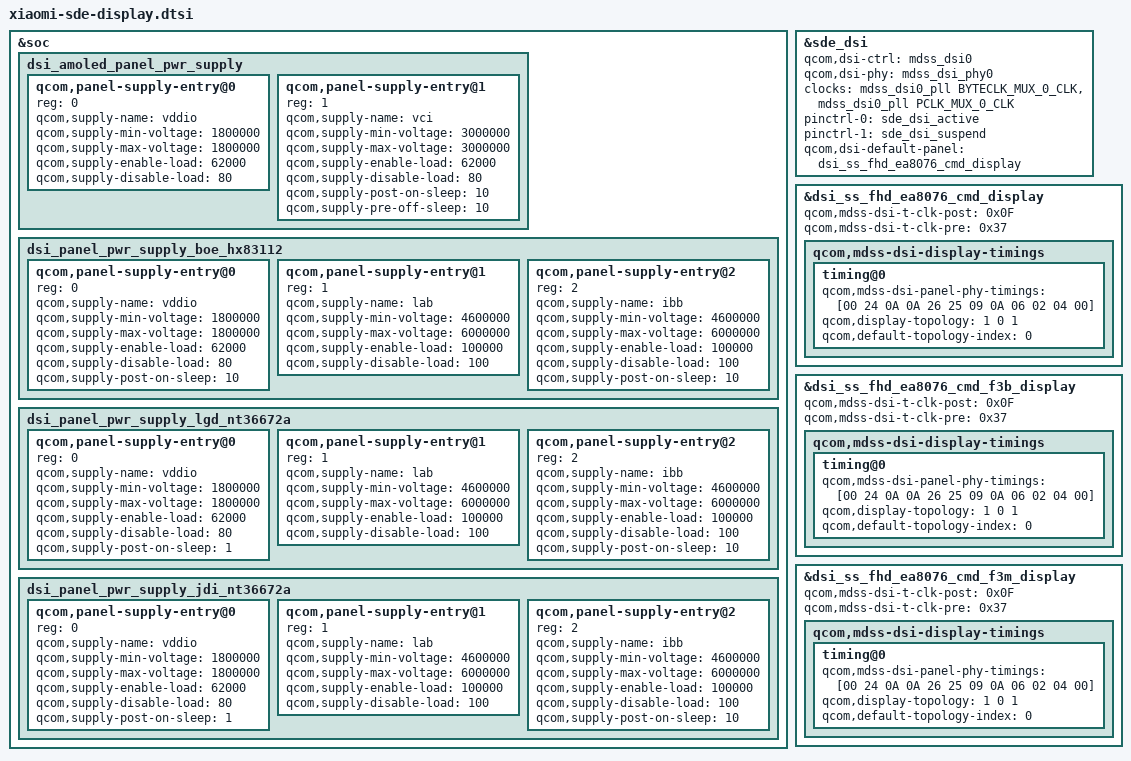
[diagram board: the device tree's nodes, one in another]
/* Copyright (c) 2017, The Linux Foundation. All rights reserved.
 * Copyright (C) 2020 XiaoMi, Inc.
 *
 * This program is free software; you can redistribute it and/or modify
 * it under the terms of the GNU General Public License version 2 and
 * only version 2 as published by the Free Software Foundation.
 *
 * This program is distributed in the hope that it will be useful,
 * but WITHOUT ANY WARRANTY; without even the implied warranty of
 * MERCHANTABILITY or FITNESS FOR A PARTICULAR PURPOSE.  See the
 * GNU General Public License for more details.
 */

#include "dsi-panel-samsung-fhd-ea8076-cmd.dtsi"
#include "dsi-panel-samsung-fhd-ea8076-cmd-f3b.dtsi"
#include "dsi-panel-samsung-fhd-ea8076-cmd-f3m.dtsi"

&soc {
	dsi_amoled_panel_pwr_supply: dsi_amoled_panel_pwr_supply {
		#address-cells = <1>;
		#size-cells = <0>;

		qcom,panel-supply-entry@0 {
			reg = <0>;
			qcom,supply-name = "vddio";
			qcom,supply-min-voltage = <1800000>;
			qcom,supply-max-voltage = <1800000>;
			qcom,supply-enable-load = <62000>;
			qcom,supply-disable-load = <80>;
		};

		qcom,panel-supply-entry@1 {
			reg = <1>;
			qcom,supply-name = "vci";
			qcom,supply-min-voltage = <3000000>;
			qcom,supply-max-voltage = <3000000>;
			qcom,supply-enable-load = <62000>;
			qcom,supply-disable-load = <80>;
			qcom,supply-post-on-sleep = <10>;
			qcom,supply-pre-off-sleep = <10>;
		};
	};

	dsi_panel_pwr_supply_boe_hx83112: dsi_panel_pwr_supply_boe_hx83112 {
		#address-cells = <1>;
		#size-cells = <0>;

		qcom,panel-supply-entry@0 {
			reg = <0>;
			qcom,supply-name = "vddio";
			qcom,supply-min-voltage = <1800000>;
			qcom,supply-max-voltage = <1800000>;
			qcom,supply-enable-load = <62000>;
			qcom,supply-disable-load = <80>;
			qcom,supply-post-on-sleep = <10>;
		};

		qcom,panel-supply-entry@1 {
			reg = <1>;
			qcom,supply-name = "lab";
			qcom,supply-min-voltage = <4600000>;
			qcom,supply-max-voltage = <6000000>;
			qcom,supply-enable-load = <100000>;
			qcom,supply-disable-load = <100>;
		};

		qcom,panel-supply-entry@2 {
			reg = <2>;
			qcom,supply-name = "ibb";
			qcom,supply-min-voltage = <4600000>;
			qcom,supply-max-voltage = <6000000>;
			qcom,supply-enable-load = <100000>;
			qcom,supply-disable-load = <100>;
			qcom,supply-post-on-sleep = <10>;
		};
	};

	dsi_panel_pwr_supply_lgd_nt36672a: dsi_panel_pwr_supply_lgd_nt36672a {
		#address-cells = <1>;
		#size-cells = <0>;

		qcom,panel-supply-entry@0 {
			reg = <0>;
			qcom,supply-name = "vddio";
			qcom,supply-min-voltage = <1800000>;
			qcom,supply-max-voltage = <1800000>;
			qcom,supply-enable-load = <62000>;
			qcom,supply-disable-load = <80>;
			qcom,supply-post-on-sleep = <1>;
		};

		qcom,panel-supply-entry@1 {
			reg = <1>;
			qcom,supply-name = "lab";
			qcom,supply-min-voltage = <4600000>;
			qcom,supply-max-voltage = <6000000>;
			qcom,supply-enable-load = <100000>;
			qcom,supply-disable-load = <100>;
		};

		qcom,panel-supply-entry@2 {
			reg = <2>;
			qcom,supply-name = "ibb";
			qcom,supply-min-voltage = <4600000>;
			qcom,supply-max-voltage = <6000000>;
			qcom,supply-enable-load = <100000>;
			qcom,supply-disable-load = <100>;
			qcom,supply-post-on-sleep = <10>;
		};
	};

	dsi_panel_pwr_supply_jdi_nt36672a: dsi_panel_pwr_supply_jdi_nt36672a {
	#address-cells = <1>;
	#size-cells = <0>;

		qcom,panel-supply-entry@0 {
			reg = <0>;
			qcom,supply-name = "vddio";
			qcom,supply-min-voltage = <1800000>;
			qcom,supply-max-voltage = <1800000>;
			qcom,supply-enable-load = <62000>;
			qcom,supply-disable-load = <80>;
			qcom,supply-post-on-sleep = <1>;
		};

		qcom,panel-supply-entry@1 {
			reg = <1>;
			qcom,supply-name = "lab";
			qcom,supply-min-voltage = <4600000>;
			qcom,supply-max-voltage = <6000000>;
			qcom,supply-enable-load = <100000>;
			qcom,supply-disable-load = <100>;
		};

		qcom,panel-supply-entry@2 {
			reg = <2>;
			qcom,supply-name = "ibb";
			qcom,supply-min-voltage = <4600000>;
			qcom,supply-max-voltage = <6000000>;
			qcom,supply-enable-load = <100000>;
			qcom,supply-disable-load = <100>;
			qcom,supply-post-on-sleep = <10>;
		};
	};
};

&sde_dsi {
	qcom,dsi-ctrl = <&mdss_dsi0>;
	qcom,dsi-phy = <&mdss_dsi_phy0>;


	clocks = <&mdss_dsi0_pll BYTECLK_MUX_0_CLK>,
			<&mdss_dsi0_pll PCLK_MUX_0_CLK>;
	clock-names = "mux_byte_clk0", "mux_pixel_clk0";
	pinctrl-names = "panel_active", "panel_suspend";
	pinctrl-0 = <&sde_dsi_active>;
	pinctrl-1 = <&sde_dsi_suspend>;
	/delete-property/ oled-vdda-supply;
	/delete-property/ qcom,platform-te-gpio;
	qcom,dsi-default-panel = <&dsi_ss_fhd_ea8076_cmd_display>;
};

&dsi_ss_fhd_ea8076_cmd_display  {
	qcom,mdss-dsi-t-clk-post = <0x0F>;
	qcom,mdss-dsi-t-clk-pre = <0x37>;
	qcom,mdss-dsi-display-timings {
		timing@0{
			qcom,mdss-dsi-panel-phy-timings = [00 24 0A 0A 26 25 09
				0A 06 02 04 00];
			qcom,display-topology = <1 0 1>;
			qcom,default-topology-index = <0>;
		};
	};
};

&dsi_ss_fhd_ea8076_cmd_f3b_display  {
	qcom,mdss-dsi-t-clk-post = <0x0F>;
	qcom,mdss-dsi-t-clk-pre = <0x37>;
	qcom,mdss-dsi-display-timings {
		timing@0{
			qcom,mdss-dsi-panel-phy-timings = [00 24 0A 0A 26 25 09
				0A 06 02 04 00];
			qcom,display-topology = <1 0 1>;
			qcom,default-topology-index = <0>;
		};
	};
};

&dsi_ss_fhd_ea8076_cmd_f3m_display  {
	qcom,mdss-dsi-t-clk-post = <0x0F>;
	qcom,mdss-dsi-t-clk-pre = <0x37>;
	qcom,mdss-dsi-display-timings {
		timing@0{
			qcom,mdss-dsi-panel-phy-timings = [00 24 0A 0A 26 25 09
				0A 06 02 04 00];
			qcom,display-topology = <1 0 1>;
			qcom,default-topology-index = <0>;
		};
	};
};
